# RP2350 register map
Vendor: Raspberry Pi; File version: 0.1
CPU: CM33 r1p0, little endian, MPU, FPU, VTOR, 4 interrupt priority bits, 54 interrupts, 8 SAU regions
Registers are 32-bit, read-write, reset 0x0 unless marked. A register's access mark holds for its fields unless they carry their own. Offsets are from the block's base; [hi:lo] are bit positions; {n}, {i} and the like mark numbered series; 'fields as' and 'values as' point back to an identical list.

## BUSCTRL — Register block for busfabric control signals and performance counters
Base 0x40068000
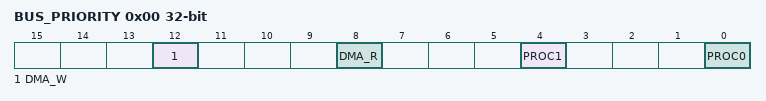
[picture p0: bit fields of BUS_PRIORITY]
0x00 BUS_PRIORITY — Set the priority of each master for bus arbitration.
  [12] DMA_W — 0 - low priority, 1 - high priority
  [8] DMA_R — 0 - low priority, 1 - high priority
  [4] PROC1 — 0 - low priority, 1 - high priority
  [0] PROC0 — 0 - low priority, 1 - high priority
0x04 BUS_PRIORITY_ACK ro — Bus priority acknowledge
  [0] BUS_PRIORITY_ACK — Goes to 1 once all arbiters have registered the new global priority levels. Arbiters update their local priority when servicing a new nonsequential access. In normal circumstances this will happen almost immediately.
0x08 PERFCTR_EN — Enable the performance counters. If 0, the performance counters do not increment. This can be used to precisely start/stop event sampling around the profiled section of code. . The performance counters are initially disabled, to save energy.
  [0] PERFCTR_EN
{0xC+8i} PERFCTR{i} (i=0..3) — Bus fabric performance counter {i}
  [23:0] PERFCTR{i} write-1-clears — Busfabric saturating performance counter {i}. Count some event signal from the busfabric arbiters, if PERFCTR_EN is set. Write any value to clear. Select an event to count using PERFSEL{i}
{0x10+8i} PERFSEL{i} reset 0x1F (i=0..3) — Bus fabric performance event select for PERFCTR{i}
  [6:0] PERFSEL{i} — Select an event for PERFCTR{i}. For each downstream port of the main crossbar, four events are available: ACCESS, an access took place; ACCESS_CONTESTED, an access took place that previously stalled due to contention from other masters; STALL_DOWNSTREAM, count cycles where any master stalled due to a stall on the downstream bus; STALL_UPSTREAM, count cycles where any master stalled for any reason, including contention from other masters.
    0=siob_proc1_stall_upstream; 1=siob_proc1_stall_downstream; 2=siob_proc1_access_contested; 3=siob_proc1_access; 4=siob_proc0_stall_upstream; 5=siob_proc0_stall_downstream; 6=siob_proc0_access_contested; 7=siob_proc0_access; 8=apb_stall_upstream; 9=apb_stall_downstream; 10=apb_access_contested; 11=apb_access; 12=fastperi_stall_upstream; 13=fastperi_stall_downstream; 14=fastperi_access_contested; 15=fastperi_access; 16=sram9_stall_upstream; 17=sram9_stall_downstream; 18=sram9_access_contested; 19=sram9_access; 20=sram8_stall_upstream; 21=sram8_stall_downstream; 22=sram8_access_contested; 23=sram8_access; 24=sram7_stall_upstream; 25=sram7_stall_downstream; 26=sram7_access_contested; 27=sram7_access; 28=sram6_stall_upstream; 29=sram6_stall_downstream; 30=sram6_access_contested; 31=sram6_access; 32=sram5_stall_upstream; 33=sram5_stall_downstream; 34=sram5_access_contested; 35=sram5_access; 36=sram4_stall_upstream; 37=sram4_stall_downstream; 38=sram4_access_contested; 39=sram4_access; 40=sram3_stall_upstream; 41=sram3_stall_downstream; 42=sram3_access_contested; 43=sram3_access; 44=sram2_stall_upstream; 45=sram2_stall_downstream; 46=sram2_access_contested; 47=sram2_access; 48=sram1_stall_upstream; 49=sram1_stall_downstream; 50=sram1_access_contested; 51=sram1_access; 52=sram0_stall_upstream; 53=sram0_stall_downstream; 54=sram0_access_contested; 55=sram0_access; 56=xip_main1_stall_upstream; 57=xip_main1_stall_downstream; 58=xip_main1_access_contested; 59=xip_main1_access; 60=xip_main0_stall_upstream; 61=xip_main0_stall_downstream; 62=xip_main0_access_contested; 63=xip_main0_access; 64=rom_stall_upstream; 65=rom_stall_downstream; 66=rom_access_contested; 67=rom_access

## ADC — Control and data interface to SAR ADC
Base 0x400A0000
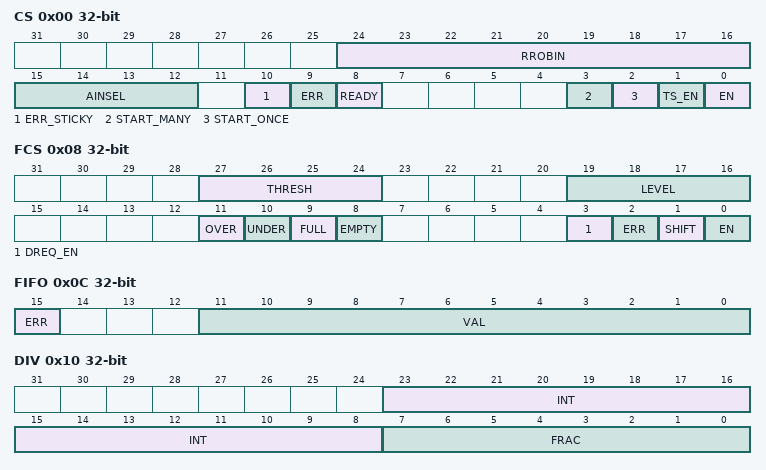
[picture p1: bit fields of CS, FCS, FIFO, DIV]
0x00 CS access per field — ADC Control and Status
  [24:16] RROBIN rw — Round-robin sampling. 1 bit per channel. Set all bits to 0 to disable. Otherwise, the ADC will cycle through each enabled channel in a round-robin fashion. The first channel to be sampled will be the one currently indicated by AINSEL. AINSEL will be updated after each conversion with the newly-selected channel.
  [15:12] AINSEL rw — Select analog mux input. Updated automatically in round-robin mode. This is corrected for the package option so only ADC channels which are bonded are available, and in the correct order
  [10] ERR_STICKY rw write-1-clears — Some past ADC conversion encountered an error. Write 1 to clear.
  [9] ERR ro — The most recent ADC conversion encountered an error; result is undefined or noisy.
  [8] READY ro — 1 if the ADC is ready to start a new conversion. Implies any previous conversion has completed. 0 whilst conversion in progress.
  [3] START_MANY rw — Continuously perform conversions whilst this bit is 1. A new conversion will start immediately after the previous finishes.
  [2] START_ONCE rw write-clears — Start a single conversion. Self-clearing. Ignored if start_many is asserted.
  [1] TS_EN rw — Power on temperature sensor. 1 - enabled. 0 - disabled.
  [0] EN rw — Power on ADC and enable its clock. 1 - enabled. 0 - disabled.
0x04 RESULT ro — Result of most recent ADC conversion
  [11:0] RESULT
0x08 FCS access per field — FIFO control and status
  [27:24] THRESH rw — DREQ/IRQ asserted when level >= threshold
  [19:16] LEVEL ro — The number of conversion results currently waiting in the FIFO
  [11] OVER rw write-1-clears — 1 if the FIFO has been overflowed. Write 1 to clear.
  [10] UNDER rw write-1-clears — 1 if the FIFO has been underflowed. Write 1 to clear.
  [9] FULL ro
  [8] EMPTY ro
  [3] DREQ_EN rw — If 1: assert DMA requests when FIFO contains data
  [2] ERR rw — If 1: conversion error bit appears in the FIFO alongside the result
  [1] SHIFT rw — If 1: FIFO results are right-shifted to be one byte in size. Enables DMA to byte buffers.
  [0] EN rw — If 1: write result to the FIFO after each conversion.
0x0C FIFO ro — Conversion result FIFO
  [15] ERR — 1 if this particular sample experienced a conversion error. Remains in the same location if the sample is shifted.
  [11:0] VAL
0x10 DIV — Clock divider. If non-zero, CS_START_MANY will start conversions at regular intervals rather than back-to-back. The divider is reset when either of these fields are written. Total period is 1 + INT + FRAC / 256
  [23:8] INT — Integer part of clock divisor.
  [7:0] FRAC — Fractional part of clock divisor. First-order delta-sigma.
0x14 INTR ro — Raw Interrupts
  [0] FIFO — Triggered when the sample FIFO reaches a certain level. This level can be programmed via the FCS_THRESH field.
0x18 INTE — Interrupt Enable
  fields as INTR
0x1C INTF — Interrupt Force
  fields as INTR
0x20 INTS ro — Interrupt status after masking & forcing
  fields as INTR
